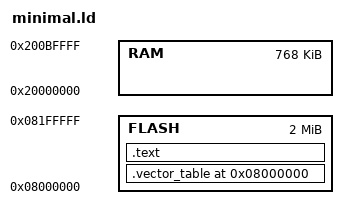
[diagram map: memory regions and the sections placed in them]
/* LabWired - Firmware Simulation Platform
 * Copyright (C) 2026 Andrii Shylenko
 *
 * This software is released under the MIT License.
 * See the LICENSE file in the project root for full license information.
 */

MEMORY
{
  FLASH : ORIGIN = 0x08000000, LENGTH = 2M
  RAM : ORIGIN = 0x20000000, LENGTH = 768K
}

ENTRY(Reset)

SECTIONS
{
  .vector_table 0x08000000 :
  {
    LONG(0x200C0000); /* Initial SP: 768 KB SRAM top */
    LONG(Reset | 1);  /* Reset handler (Thumb bit set) */
  } > FLASH

  .text :
  {
    *(.text*)
    *(.rodata*)
  } > FLASH

  /DISCARD/ :
  {
    *(.ARM.exidx*)
    *(.note.gnu.build-id*)
  }
}
